# Template register map
Vendor: VendorName Co.Ltd; Series: SeriesName; File version: 1.2
CPU: CM7 r0p1, little endian, MPU, FPU, 4 interrupt priority bits
Registers are 32-bit, read-write, no defined reset value unless marked. A register's access mark holds for its fields unless they carry their own. Offsets are from the block's base; [hi:lo] are bit positions; {n}, {i} and the like mark numbered series.

## EPG — Embedded Pattern Generator
Base 0x4006A000
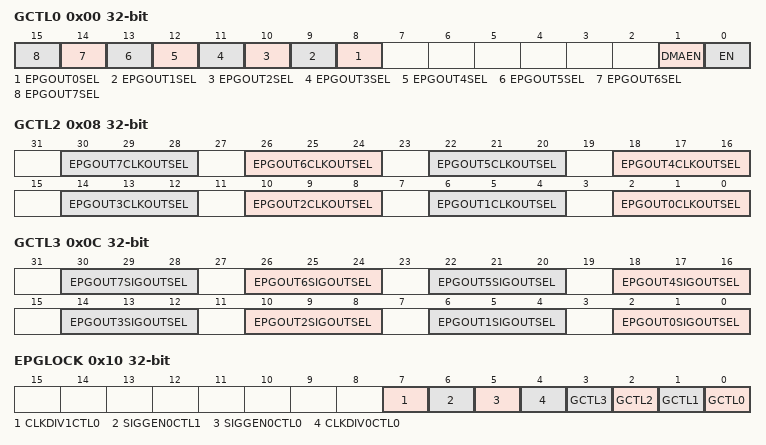
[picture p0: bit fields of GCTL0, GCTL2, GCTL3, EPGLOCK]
0x00 GCTL0 — EPG global control register 0
  [n+8] EPGOUT{n}SEL (n=0..7) — EPG EPGOUT{n}SEL bit: EPG output {n} selelt
  [1] DMAEN — EPG DMAEN bit: DMA enable
  [0] EN — EPG EN bit: EPG module enable
0x04 GCTL1 — EPG global control register 1
  [2:0] SIGGEN0CLKSEL — EPG SIGGEN0CLKSEL[2:0] bit: clock source select of SIGGEN0
0x08 GCTL2 — EPG global control register 2
  [4n+2:4n] EPGOUT{n}CLKOUTSEL (n=0..7) — EPG EPGOUT{n}CLKOUTSEL[2:0] bit: output {n} signal source select
0x0C GCTL3 — EPG global control register 3
  [4n+2:4n] EPGOUT{n}SIGOUTSEL (n=0..7) — EPG EPGOUT{n}SIGOUTSEL[2:0] bit: output {n} source select
0x10 EPGLOCK — EPG lock configuration register
  [7] CLKDIV1CTL0 — EPG CLKDIV1CTL0 bit: CLKDIV1CTL0 register write enable
  [6] SIGGEN0CTL1 — EPG SIGGEN0CTL1 bit: SIGGEN0CTL1 register write enable
  [5] SIGGEN0CTL0 — EPG SIGGEN0CTL0 bit: SIGGEN0CTL0 register write enable
  [4] CLKDIV0CTL0 — EPG CLKDIV0CTL0 bit: CLKDIV0CTL0 register write enable
  [n] GCTL{n} (n=0..3) — EPG GCTL{n} bit: GCTL{n} register write enable
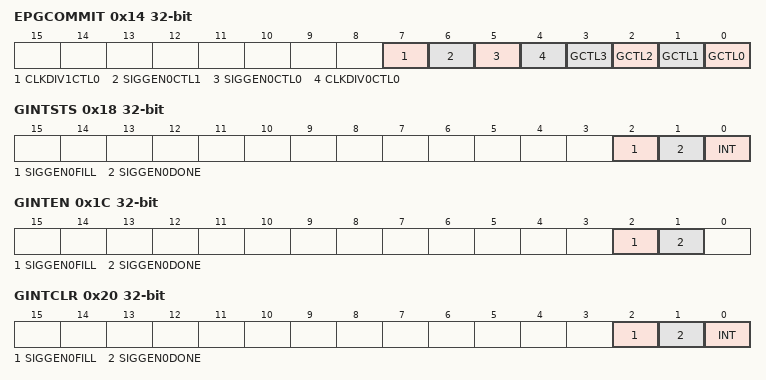
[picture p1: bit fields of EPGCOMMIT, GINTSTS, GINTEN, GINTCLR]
0x14 EPGCOMMIT — EPG lock the configuration COMMIT register
  [7] CLKDIV1CTL0 — EPG CLKDIV1CTL0 bit: CLKDIV1CTL0 bit write enable
  [6] SIGGEN0CTL1 — EPG SIGGEN0CTL1 bit: SIGGEN0CTL1 bit write enable
  [5] SIGGEN0CTL0 — EPG SIGGEN0CTL0 bit: SIGGEN0CTL0 bit write enable
  [4] CLKDIV0CTL0 — EPG CLKDIV0CTL0 bit: CLKDIV0CTL0 bit write enable
  [n] GCTL{n} (n=0..3) — EPG GCTL{n} bit: GCTL{n} bit write enable
0x18 GINTSTS ro — EPG global interrupt status register
  [2] SIGGEN0FILL — EPG SIGGEN0FILL bit: enable selection of interrupt generation when SIGGEN0FILL bits is set
  [1] SIGGEN0DONE — EPG SIGGEN0DONE bit: enable selection of interrupt generation when SIGGEN0DONE bits is set
  [0] INT — EPG INT bit: global interrupt flag
0x1C GINTEN — EPG global interrupt enable register
  [2] SIGGEN0FILL — EPG SIGGEN0FILL bit: SIGGEN0FILL bit interrupt enable
  [1] SIGGEN0DONE — EPG SIGGEN0DONE bit: SIGGEN0DONE bit interrupt enable
0x20 GINTCLR wo — EPG global interrupt clear register
  [2] SIGGEN0FILL — EPG SIGGEN0FILL bit: SIGGEN0FILL flag bit clear enable
  [1] SIGGEN0DONE — EPG SIGGEN0DONE bit: SIGGEN0DONE flag bit clear enable
  [0] INT — EPG INT bit: INT flag bit clear enable
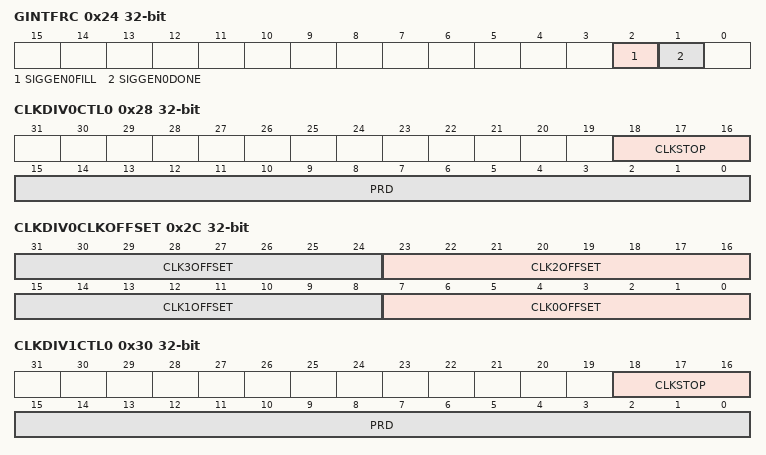
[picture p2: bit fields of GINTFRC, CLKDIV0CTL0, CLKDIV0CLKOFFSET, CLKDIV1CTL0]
0x24 GINTFRC wo — EPG global software force interrupt register
  [2] SIGGEN0FILL — EPG SIGGEN0FILL bit: SIGGEN0FILL software generate interrupt
  [1] SIGGEN0DONE — EPG SIGGEN0DONE bit: SIGGEN0DONE software generate interrupt
0x28 CLKDIV0CTL0 — EPG clock divider 0 control register
  [18:16] CLKSTOP — EPG CLKSTOP[2:0] bit: determines on which of the CLKOUTs edge clock generation is stopped 0
  [15:0] PRD — EPG PRD[15:0] bit: Clock divider period 0
0x2C CLKDIV0CLKOFFSET — EPG clock divider 0 clock offset register
  [8n+7:8n] CLK{n}OFFSET (n=0..3) — EPG CLK{n}OFFSET[7:0] bit: number of source clock cycles by which the divided clock output {n} is delayed 0
0x30 CLKDIV1CTL0 — EPG clock divider 1 control register
  [18:16] CLKSTOP — EPG CLKSTOP[2:0] bit: determines on which of the CLKOUTs edge clock generation is stopped 1
  [15:0] PRD — EPG PRD[15:0] bit: clock divider period 1
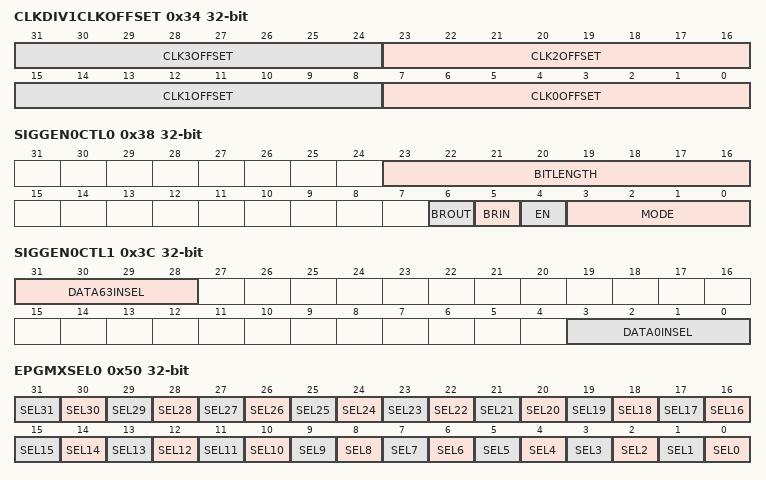
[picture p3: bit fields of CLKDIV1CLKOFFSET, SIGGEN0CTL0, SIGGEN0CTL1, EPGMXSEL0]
0x34 CLKDIV1CLKOFFSET — EPG clock divider 1 clock shift register
  [8n+7:8n] CLK{n}OFFSET (n=0..3) — EPG CLK{n}OFFSET[7:0] bit: number of source clock cycles by which the divided clock output {n} is delayed 1
0x38 SIGGEN0CTL0 — EPG vector generator 0 controls register
  [23:16] BITLENGTH — EPG BITLENGTH[7:0] bit: defines the number bits
  [6] BROUT — EPG BROUT bit: select of bit reversal on data output
  [5] BRIN — EPG BRIN bit: select of bit reversal on data input
  [4] EN — EPG EN bit: signal generator enable
  [3:0] MODE — EPG MODE[3:0] bit: mode select
0x3C SIGGEN0CTL1 — EPG vector generator 0 controls register
  [31:28] DATA63INSEL — EPG DATA63INSEL[3:0] bit: source input of bit 63 of Data register
  [3:0] DATA0INSEL — EPG DATA0INSEL[3:0] bit: source input of bit 0 of Data register
0x40 SIGGEN0DATA0 — EPG vector generator 0 data register
  [31:0] SIGGENDATA0 — EPG SIGGENDATA0[31:0] bit: data 0 used in signal bit stream
0x44 SIGGEN0DATA1 — EPG vector generator 0 data register 1
  [31:0] SIGGENDATA1 — EPG SIGGENDATA1[31:0] bit: data 1 used in signal bit stream
0x48 SIGGEN0DATA0ACTIVE ro — EPG vector generator 0 data valid register 0
  [31:0] SIGENDATA0 — EPG SIGENDATA0[31:0] bit: this is the lower 32 bits of the 64 bit active register
0x4C SIGGEN0DATA1ACTIVE ro — EPG vector generator 0 data valid register 1
  [31:0] SIGGENDATA1 — EPG SIGGENDATA1[31:0] bit: this is the upper 32 bits of the 64 bit active register
0x50 EPGMXSEL0 — EPG MUX select register 0
  [n] SEL{n} (n=0..31) — EPG SEL{n} bit: select {n}
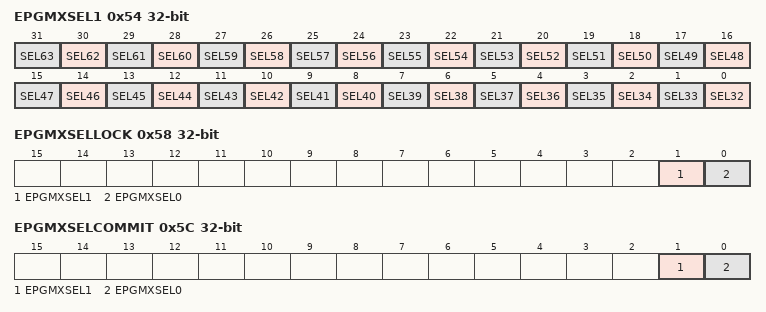
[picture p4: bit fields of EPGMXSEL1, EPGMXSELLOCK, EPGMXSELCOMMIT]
0x54 EPGMXSEL1 — EPG MUX select register 1
  [n-32] SEL{n} (n=32..63) — EPG SEL{n} bit: select {n}
0x58 EPGMXSELLOCK — EPG MUX lock configuration register
  [1] EPGMXSEL1 — EPG EPGMXSEL1 bit: EPGMXSEL1 register write enable
  [0] EPGMXSEL0 — EPG EPGMXSEL0 bit: EPGMXSEL0 register write enable
0x5C EPGMXSELCOMMIT — EPG MUX lock the configuration COMMIT register
  [1] EPGMXSEL1 — EPG EPGMXSEL1 bit: EPGMXSEL1 bit write enable
  [0] EPGMXSEL0 — EPG EPGMXSEL0 bit: EPGMXSEL0 bit write enable
